# STM32H750x register map
File version: 1.8
CPU: CM7 r0p1, little endian, MPU, FPU, 4 interrupt priority bits
Registers are 32-bit, read-write, reset 0x0 unless marked. A register's access mark holds for its fields unless they carry their own. Offsets are from the block's base; [hi:lo] are bit positions; {n}, {i} and the like mark numbered series.

## TIM6 — Basic timers
Base 0x40001000
Same registers: TIM7 0x40001400
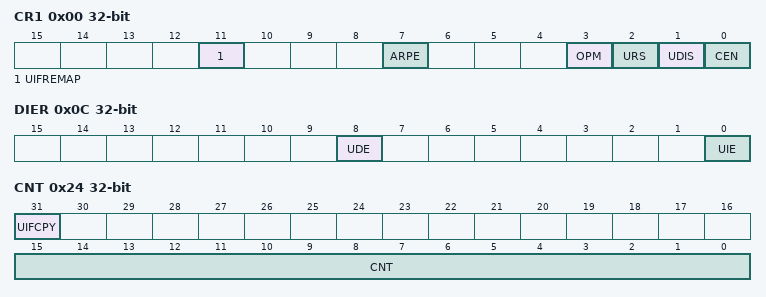
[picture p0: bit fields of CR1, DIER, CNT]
0x00 CR1 — control register 1
  [11] UIFREMAP — UIF status bit remapping
  [7] ARPE — Auto-reload preload enable
  [3] OPM — One-pulse mode
  [2] URS — Update request source
  [1] UDIS — Update disable
  [0] CEN — Counter enable
0x04 CR2 — control register 2
  [6:4] MMS — Master mode selection
0x0C DIER — DMA/Interrupt enable register
  [8] UDE — Update DMA request enable
  [0] UIE — Update interrupt enable
0x10 SR — status register
  [0] UIF — Update interrupt flag
0x14 EGR wo — event generation register
  [0] UG — Update generation
0x24 CNT — counter
  [31] UIFCPY — UIF Copy
  [15:0] CNT — Low counter value
0x28 PSC — prescaler
  [15:0] PSC — Prescaler value
0x2C ARR — auto-reload register
  [15:0] ARR — Low Auto-reload value

## NVIC — Nested Vectored Interrupt Controller
Base 0xE000E100
{0x0+4i} ISER{i} (i=0..2) — Interrupt Set-Enable Register
  [31:0] SETENA
{0x80+4i} ICER{i} (i=0..2) — Interrupt Clear-Enable Register
  [31:0] CLRENA
{0x100+4i} ISPR{i} (i=0..2) — Interrupt Set-Pending Register
  [31:0] SETPEND
{0x180+4i} ICPR{i} (i=0..2) — Interrupt Clear-Pending Register
  [31:0] CLRPEND
{0x200+4i} IABR{i} ro (i=0..2) — Interrupt Active Bit Register
  [31:0] ACTIVE
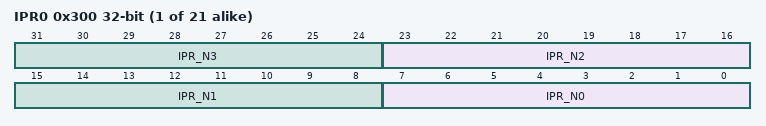
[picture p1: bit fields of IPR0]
{0x300+4i} IPR{i} (i=0..20) — Interrupt Priority Register
  [8n+7:8n] IPR_N{n} (n=0..3)

## DBGMCU — Microcontroller Debug Unit
Base 0x5C001000
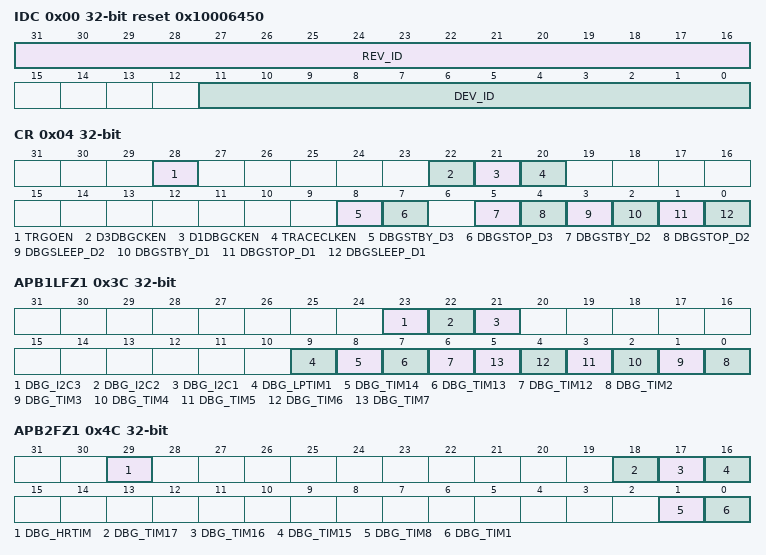
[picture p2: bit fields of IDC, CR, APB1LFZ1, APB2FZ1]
0x00 IDC ro reset 0x10006450 — DBGMCU Identity Code Register
  [31:16] REV_ID — Revision
  [11:0] DEV_ID — Device ID
0x04 CR — DBGMCU Configuration Register
  [28] TRGOEN — External trigger output enable
  [22] D3DBGCKEN — D3 debug clock enable
  [21] D1DBGCKEN — D1 debug clock enable
  [20] TRACECLKEN — Trace port clock enable
  [8] DBGSTBY_D3 — Allow debug in D3 Standby mode
  [7] DBGSTOP_D3 — Allow debug in D3 Stop mode
  [5] DBGSTBY_D2 — Allow D2 domain debug in Standby mode
  [4] DBGSTOP_D2 — Allow D2 domain debug in Stop mode
  [3] DBGSLEEP_D2 — Allow D2 domain debug in Sleep mode
  [2] DBGSTBY_D1 — Allow D1 domain debug in Standby mode
  [1] DBGSTOP_D1 — Allow D1 domain debug in Stop mode
  [0] DBGSLEEP_D1 — Allow D1 domain debug in Sleep mode
0x34 APB3FZ1 — DBGMCU APB3 peripheral freeze register
  [6] WWDG1 — WWDG1 stop in debug
0x3C APB1LFZ1 — DBGMCU APB1L peripheral freeze register
  [23] DBG_I2C3 — I2C3 SMBUS timeout stop in debug
  [22] DBG_I2C2 — I2C2 SMBUS timeout stop in debug
  [21] DBG_I2C1 — I2C1 SMBUS timeout stop in debug
  [9] DBG_LPTIM1 — LPTIM1 stop in debug
  [8] DBG_TIM14 — TIM14 stop in debug
  [7] DBG_TIM13 — TIM13 stop in debug
  [6] DBG_TIM12 — TIM12 stop in debug
  [n-2] DBG_TIM{n} (n=2..7) — TIM{n} stop in debug
0x4C APB2FZ1 — DBGMCU APB2 peripheral freeze register
  [29] DBG_HRTIM — HRTIM stop in debug
  [18] DBG_TIM17 — TIM17 stop in debug
  [17] DBG_TIM16 — TIM16 stop in debug
  [16] DBG_TIM15 — TIM15 stop in debug
  [1] DBG_TIM8 — TIM8 stop in debug
  [0] DBG_TIM1 — TIM1 stop in debug
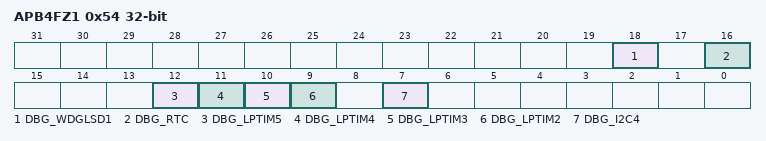
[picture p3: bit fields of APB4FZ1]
0x54 APB4FZ1 — DBGMCU APB4 peripheral freeze register
  [18] DBG_WDGLSD1 — Independent watchdog for D1 stop in debug
  [16] DBG_RTC — RTC stop in debug
  [12] DBG_LPTIM5 — LPTIM5 stop in debug
  [11] DBG_LPTIM4 — LPTIM4 stop in debug
  [10] DBG_LPTIM3 — LPTIM2 stop in debug
  [9] DBG_LPTIM2 — LPTIM2 stop in debug
  [7] DBG_I2C4 — I2C4 SMBUS timeout stop in debug

## MPU — Memory protection unit
Base 0xE000ED90
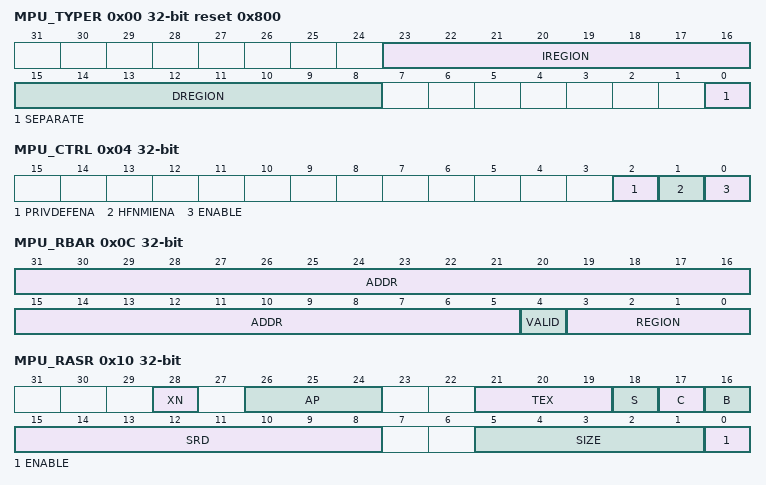
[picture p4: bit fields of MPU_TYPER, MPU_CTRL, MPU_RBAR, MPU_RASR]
0x00 MPU_TYPER ro reset 0x800 — MPU type register
  [23:16] IREGION — Number of MPU instruction regions
  [15:8] DREGION — Number of MPU data regions
  [0] SEPARATE — Separate flag
0x04 MPU_CTRL — MPU control register
  [2] PRIVDEFENA — Enable priviliged software access to default memory map
  [1] HFNMIENA — Enables the operation of MPU during hard fault
  [0] ENABLE — Enables the MPU
0x08 MPU_RNR — MPU region number register
  [7:0] REGION — MPU region
0x0C MPU_RBAR — MPU region base address register
  [31:5] ADDR — Region base address field
  [4] VALID — MPU region number valid
  [3:0] REGION — MPU region field
0x10 MPU_RASR — MPU region attribute and size register
  [28] XN — Instruction access disable bit
  [26:24] AP — Access permission
  [21:19] TEX — memory attribute
  [18] S — Shareable memory attribute
  [17] C — memory attribute
  [16] B — memory attribute
  [15:8] SRD — Subregion disable bits
  [5:1] SIZE — Size of the MPU protection region
  [0] ENABLE — Region enable bit.

## STK — SysTick timer
Base 0xE000E010
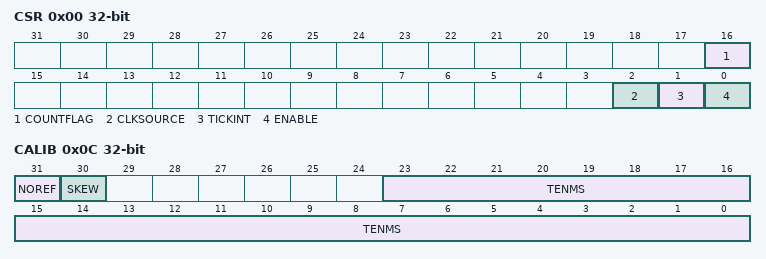
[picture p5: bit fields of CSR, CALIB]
0x00 CSR — SysTick control and status register
  [16] COUNTFLAG
  [2] CLKSOURCE — Clock source selection
  [1] TICKINT — SysTick exception request enable
  [0] ENABLE — Counter enable
0x04 RVR — SysTick reload value register
  [23:0] RELOAD — RELOAD value
0x08 CVR — SysTick current value register
  [23:0] CURRENT — Current counter value
0x0C CALIB — SysTick calibration value register
  [31] NOREF — NOREF flag. Reads as zero
  [30] SKEW — SKEW flag: Indicates whether the TENMS value is exact
  [23:0] TENMS — Calibration value

## NVIC_STIR — Nested vectored interrupt controller
Base 0xE000EF00
0x00 STIR — Software trigger interrupt register
  [8:0] INTID — Software generated interrupt ID

## FPU_CPACR — Floating point unit CPACR
Base 0xE000ED88
0x00 CPACR — Coprocessor access control register
  [23:20] CP

## SCB_ACTRL — System control block ACTLR
Base 0xE000E008
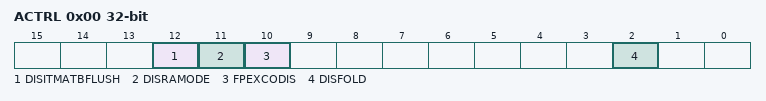
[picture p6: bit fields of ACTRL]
0x00 ACTRL — Auxiliary control register
  [12] DISITMATBFLUSH, [11] DISRAMODE, [10] FPEXCODIS, [2] DISFOLD

## FPU — Floting point unit
Base 0xE000EF34
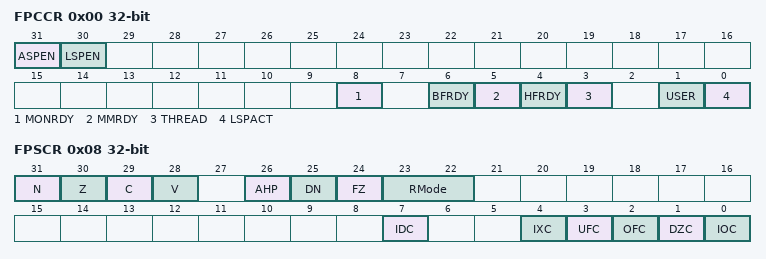
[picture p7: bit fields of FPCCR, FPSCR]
0x00 FPCCR — Floating-point context control register
  [31] ASPEN, [30] LSPEN, [8] MONRDY, [6] BFRDY, [5] MMRDY, [4] HFRDY, [3] THREAD, [1] USER, [0] LSPACT
0x04 FPCAR — Floating-point context address register
  [31:3] ADDRESS — Location of unpopulated floating-point
0x08 FPSCR — Floating-point status control register
  [31] N — Negative condition code flag
  [30] Z — Zero condition code flag
  [29] C — Carry condition code flag
  [28] V — Overflow condition code flag
  [26] AHP — Alternative half-precision control bit
  [25] DN — Default NaN mode control bit
  [24] FZ — Flush-to-zero mode control bit:
  [23:22] RMode — Rounding Mode control field
  [7] IDC — Input denormal cumulative exception bit.
  [4] IXC — Inexact cumulative exception bit
  [3] UFC — Underflow cumulative exception bit
  [2] OFC — Overflow cumulative exception bit
  [1] DZC — Division by zero cumulative exception bit.
  [0] IOC — Invalid operation cumulative exception bit

## PF — Processor features
Base 0xE000ED78
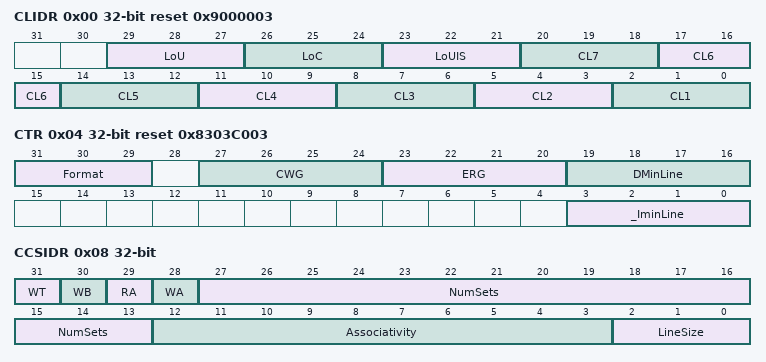
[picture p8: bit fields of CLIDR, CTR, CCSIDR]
0x00 CLIDR ro reset 0x9000003 — Cache Level ID register
  [29:27] LoU, [26:24] LoC, [23:21] LoUIS, [3n-1:3n-3] CL{n} (n=1..7)
0x04 CTR ro reset 0x8303C003 — Cache Type register
  [31:29] Format, [27:24] CWG, [23:20] ERG, [19:16] DMinLine, [3:0] _IminLine
0x08 CCSIDR ro — Cache Size ID register
  [31] WT, [30] WB, [29] RA, [28] WA, [27:13] NumSets, [12:3] Associativity, [2:0] LineSize

## AC — Access control
Base 0xE000EF90
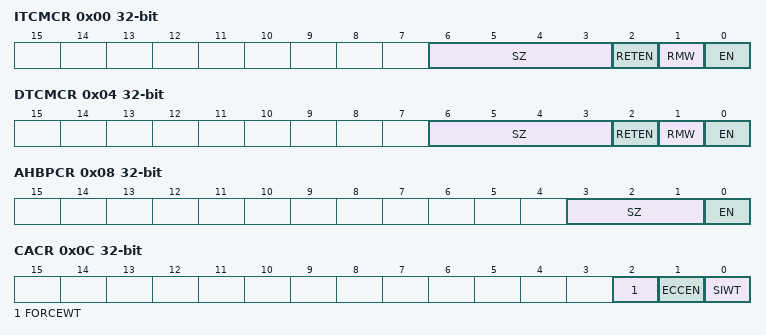
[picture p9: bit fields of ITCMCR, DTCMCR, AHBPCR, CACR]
0x00 ITCMCR — Instruction and Data Tightly-Coupled Memory Control Registers
  [6:3] SZ, [2] RETEN, [1] RMW, [0] EN
0x04 DTCMCR — Instruction and Data Tightly-Coupled Memory Control Registers
  [6:3] SZ, [2] RETEN, [1] RMW, [0] EN
0x08 AHBPCR — AHBP Control register
  [3:1] SZ, [0] EN
0x0C CACR — Auxiliary Cache Control register
  [2] FORCEWT, [1] ECCEN, [0] SIWT
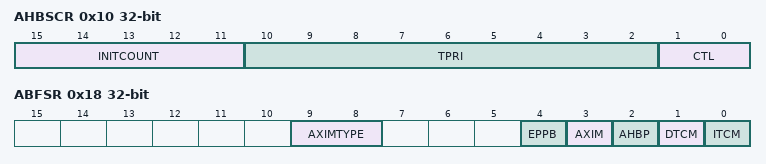
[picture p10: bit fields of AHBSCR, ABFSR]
0x10 AHBSCR — AHB Slave Control register
  [15:11] INITCOUNT, [10:2] TPRI, [1:0] CTL
0x18 ABFSR — Auxiliary Bus Fault Status register
  [9:8] AXIMTYPE, [4] EPPB, [3] AXIM, [2] AHBP, [1] DTCM, [0] ITCM

## Notices in the file
Copyright (c) 2021 STMicroelectronics.
SPDX-License-Identifier: Apache-2.0
Licensed under the Apache License, Version 2.0 (the "License");
you may not use this file except in compliance with the License.
You may obtain a copy of the License at
http://www.apache.org/licenses/LICENSE-2.0
Unless required by applicable law or agreed to in writing, software
distributed under the License is distributed on an "AS IS" BASIS,
WITHOUT WARRANTIES OR CONDITIONS OF ANY KIND, either express or implied.
See the License for the specific language governing permissions and
limitations under the License.
